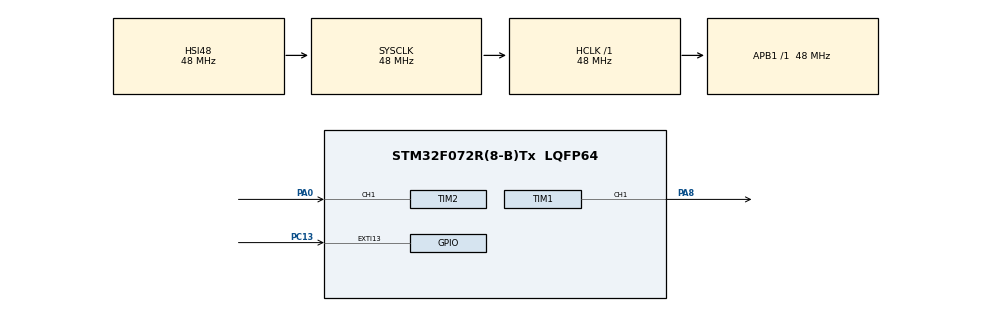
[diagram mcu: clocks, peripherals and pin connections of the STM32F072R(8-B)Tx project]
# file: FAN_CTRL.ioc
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Mcu.Family=STM32F0
Mcu.Name=STM32F072R(8-B)Tx
Mcu.Package=LQFP64
NVIC.EXTI4_15_IRQn=true\:0\:0\:false\:false\:true\:true\:true\:true
NVIC.TIM2_IRQn=true\:0\:0\:false\:false\:true\:true\:true\:true
PA0.GPIO_PuPd=GPIO_PULLUP
PA0.Signal=S_TIM2_CH1_ETR
PA13.Mode=Serial_Wire
PA13.Signal=SYS_SWDIO
PA14.Mode=Serial_Wire
PA14.Signal=SYS_SWCLK
PA8.Signal=S_TIM1_CH1
PC13.GPIO_ModeDefaultEXTI=GPIO_MODE_IT_FALLING
PC13.GPIO_PuPd=GPIO_PULLUP
PC13.Signal=GPXTI13
ProjectManager.HeapSize=0x200
ProjectManager.StackSize=0x400
ProjectManager.TargetToolchain=STM32CubeIDE
RCC.AHBFreq_Value=48000000
RCC.APB1Freq_Value=48000000
RCC.APB1TimFreq_Value=48000000
RCC.FLatency-AdvancedSettings=FLASH_LATENCY_1
RCC.HCLKFreq_Value=48000000
RCC.PLLDivider=RCC_PREDIV_DIV2
RCC.PLLMUL=RCC_PLL_MUL12
RCC.PREFETCH_ENABLE-AdvancedSettings=1
RCC.SYSCLKFreq_VALUE=48000000
RCC.SYSCLKSource=RCC_SYSCLKSOURCE_HSI48
SH.S_TIM1_CH1.0=TIM1_CH1,PWM Generation1 CH1
SH.S_TIM2_CH1_ETR.0=TIM2_CH1,Input_Capture1_from_TI1
TIM1.Channel-PWM\ Generation1\ CH1=TIM_CHANNEL_1
TIM1.Period=100-1
TIM1.Prescaler=48-1
TIM2.Channel-Input_Capture1_from_TI1=TIM_CHANNEL_1
TIM2.ICPolarity_CH1=TIM_INPUTCHANNELPOLARITY_RISING
TIM2.Period=0xffffffff-1
TIM2.Prescaler=48-1
VP_TIM1_VS_ClockSourceINT.Mode=Internal
VP_TIM2_VS_ClockSourceINT.Mode=Internal
board=NUCLEO-F072RB

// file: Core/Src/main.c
/* USER CODE BEGIN Header */
/**
  ******************************************************************************
  * @file           : main.c
  * @brief          : Main program body
  ******************************************************************************
  * @attention
  *
  * Copyright (c) 2024 STMicroelectronics.
  * All rights reserved.
  *
  * This software is licensed under terms that can be found in the LICENSE file
  * in the root directory of this software component.
  * If no LICENSE file comes with this software, it is provided AS-IS.
  *
  ******************************************************************************
  */
/* USER CODE END Header */
#include "main.h"

/* USER CODE BEGIN Includes */
#include "stdbool.h"
/* USER CODE END Includes */

TIM_HandleTypeDef htim1;
TIM_HandleTypeDef htim2;

void SystemClock_Config(void);
static void MX_GPIO_Init(void);
static void MX_TIM1_Init(void);
static void MX_TIM2_Init(void);

/* USER CODE BEGIN 0 */
static uint8_t duty = 0;
void HAL_GPIO_EXTI_Callback(uint16_t GPIO_Pin)
{
    if(GPIO_PIN_13 == GPIO_Pin) {
        if (GPIO_PIN_RESET == HAL_GPIO_ReadPin(GPIOC, GPIO_Pin))
        {
        	if (100 < (duty += 10)) {
        		duty = 0;
        	}
        	TIM1->CCR1 = duty;
        }
    }
}

static bool isFirstCap = true;
static uint32_t ic1 = 0;
static uint32_t ic2 = 0;
static float icFreq = 0;
#define REF_FREQ (48000000 / 48)

void HAL_TIM_IC_CaptureCallback(TIM_HandleTypeDef *htim)
{
	if (HAL_TIM_ACTIVE_CHANNEL_1 == htim->Channel)
	{
		if (true == isFirstCap)
		{
			ic1 = HAL_TIM_ReadCapturedValue(htim, TIM_CHANNEL_1);
			isFirstCap = false;
		}
		else
		{
			ic2 = HAL_TIM_ReadCapturedValue(htim, TIM_CHANNEL_1);  // read second value

			uint32_t diff;
			if (ic2 >= ic1)
			{
				diff = ic2 - ic1;
			}
			else
			{
				diff = (0xffffffff - ic1) + ic2;
			}

			ic1 = ic2;
			icFreq = REF_FREQ / diff;
		}
	}
}

/* USER CODE END 0 */

int main(void)
{

  /* MCU Configuration--------------------------------------------------------*/

  /* Reset of all peripherals, Initializes the Flash interface and the Systick. */
  HAL_Init();

  /* Configure the system clock */
  SystemClock_Config();

  /* Initialize all configured peripherals */
  MX_GPIO_Init();
  MX_TIM1_Init();
  MX_TIM2_Init();
  /* USER CODE BEGIN 2 */
  TIM1->CCR1 = 100;
  HAL_TIM_PWM_Start(&htim1, TIM_CHANNEL_1);
  HAL_TIM_IC_Start_IT(&htim2, TIM_CHANNEL_1);

  /* USER CODE END 2 */

  /* Infinite loop */
  while (1)
  {

  }
}

void SystemClock_Config(void)
{
  RCC_OscInitTypeDef RCC_OscInitStruct = {0};
  RCC_ClkInitTypeDef RCC_ClkInitStruct = {0};

  /** Initializes the RCC Oscillators according to the specified parameters
  * in the RCC_OscInitTypeDef structure.
  */
  RCC_OscInitStruct.OscillatorType = RCC_OSCILLATORTYPE_HSI48;
  RCC_OscInitStruct.HSI48State = RCC_HSI48_ON;
  RCC_OscInitStruct.PLL.PLLState = RCC_PLL_NONE;
  if (HAL_RCC_OscConfig(&RCC_OscInitStruct) != HAL_OK)
  {
    Error_Handler();
  }

  /** Initializes the CPU, AHB and APB buses clocks
  */
  RCC_ClkInitStruct.ClockType = RCC_CLOCKTYPE_HCLK|RCC_CLOCKTYPE_SYSCLK
                              |RCC_CLOCKTYPE_PCLK1;
  RCC_ClkInitStruct.SYSCLKSource = RCC_SYSCLKSOURCE_HSI48;
  RCC_ClkInitStruct.AHBCLKDivider = RCC_SYSCLK_DIV1;
  RCC_ClkInitStruct.APB1CLKDivider = RCC_HCLK_DIV1;

  if (HAL_RCC_ClockConfig(&RCC_ClkInitStruct, FLASH_LATENCY_1) != HAL_OK)
  {
    Error_Handler();
  }
}

static void MX_TIM1_Init(void)
{

  TIM_ClockConfigTypeDef sClockSourceConfig = {0};
  TIM_MasterConfigTypeDef sMasterConfig = {0};
  TIM_OC_InitTypeDef sConfigOC = {0};
  TIM_BreakDeadTimeConfigTypeDef sBreakDeadTimeConfig = {0};

  htim1.Instance = TIM1;
  htim1.Init.Prescaler = 48-1;
  htim1.Init.CounterMode = TIM_COUNTERMODE_UP;
  htim1.Init.Period = 100-1;
  htim1.Init.ClockDivision = TIM_CLOCKDIVISION_DIV1;
  htim1.Init.RepetitionCounter = 0;
  htim1.Init.AutoReloadPreload = TIM_AUTORELOAD_PRELOAD_DISABLE;
  if (HAL_TIM_Base_Init(&htim1) != HAL_OK)
  {
    Error_Handler();
  }
  sClockSourceConfig.ClockSource = TIM_CLOCKSOURCE_INTERNAL;
  if (HAL_TIM_ConfigClockSource(&htim1, &sClockSourceConfig) != HAL_OK)
  {
    Error_Handler();
  }
  if (HAL_TIM_PWM_Init(&htim1) != HAL_OK)
  {
    Error_Handler();
  }
  sMasterConfig.MasterOutputTrigger = TIM_TRGO_RESET;
  sMasterConfig.MasterSlaveMode = TIM_MASTERSLAVEMODE_DISABLE;
  if (HAL_TIMEx_MasterConfigSynchronization(&htim1, &sMasterConfig) != HAL_OK)
  {
    Error_Handler();
  }
  sConfigOC.OCMode = TIM_OCMODE_PWM1;
  sConfigOC.Pulse = 0;
  sConfigOC.OCPolarity = TIM_OCPOLARITY_HIGH;
  sConfigOC.OCNPolarity = TIM_OCNPOLARITY_HIGH;
  sConfigOC.OCFastMode = TIM_OCFAST_DISABLE;
  sConfigOC.OCIdleState = TIM_OCIDLESTATE_RESET;
  sConfigOC.OCNIdleState = TIM_OCNIDLESTATE_RESET;
  if (HAL_TIM_PWM_ConfigChannel(&htim1, &sConfigOC, TIM_CHANNEL_1) != HAL_OK)
  {
    Error_Handler();
  }
  sBreakDeadTimeConfig.OffStateRunMode = TIM_OSSR_DISABLE;
  sBreakDeadTimeConfig.OffStateIDLEMode = TIM_OSSI_DISABLE;
  sBreakDeadTimeConfig.LockLevel = TIM_LOCKLEVEL_OFF;
  sBreakDeadTimeConfig.DeadTime = 0;
  sBreakDeadTimeConfig.BreakState = TIM_BREAK_DISABLE;
  sBreakDeadTimeConfig.BreakPolarity = TIM_BREAKPOLARITY_HIGH;
  sBreakDeadTimeConfig.AutomaticOutput = TIM_AUTOMATICOUTPUT_DISABLE;
  if (HAL_TIMEx_ConfigBreakDeadTime(&htim1, &sBreakDeadTimeConfig) != HAL_OK)
  {
    Error_Handler();
  }
  HAL_TIM_MspPostInit(&htim1);

}

static void MX_TIM2_Init(void)
{

  TIM_ClockConfigTypeDef sClockSourceConfig = {0};
  TIM_MasterConfigTypeDef sMasterConfig = {0};
  TIM_IC_InitTypeDef sConfigIC = {0};

  htim2.Instance = TIM2;
  htim2.Init.Prescaler = 48-1;
  htim2.Init.CounterMode = TIM_COUNTERMODE_UP;
  htim2.Init.Period = 0xffffffff-1;
  htim2.Init.ClockDivision = TIM_CLOCKDIVISION_DIV1;
  htim2.Init.AutoReloadPreload = TIM_AUTORELOAD_PRELOAD_DISABLE;
  if (HAL_TIM_Base_Init(&htim2) != HAL_OK)
  {
    Error_Handler();
  }
  sClockSourceConfig.ClockSource = TIM_CLOCKSOURCE_INTERNAL;
  if (HAL_TIM_ConfigClockSource(&htim2, &sClockSourceConfig) != HAL_OK)
  {
    Error_Handler();
  }
  if (HAL_TIM_IC_Init(&htim2) != HAL_OK)
  {
    Error_Handler();
  }
  sMasterConfig.MasterOutputTrigger = TIM_TRGO_RESET;
  sMasterConfig.MasterSlaveMode = TIM_MASTERSLAVEMODE_DISABLE;
  if (HAL_TIMEx_MasterConfigSynchronization(&htim2, &sMasterConfig) != HAL_OK)
  {
    Error_Handler();
  }
  sConfigIC.ICPolarity = TIM_INPUTCHANNELPOLARITY_RISING;
  sConfigIC.ICSelection = TIM_ICSELECTION_DIRECTTI;
  sConfigIC.ICPrescaler = TIM_ICPSC_DIV1;
  sConfigIC.ICFilter = 0;
  if (HAL_TIM_IC_ConfigChannel(&htim2, &sConfigIC, TIM_CHANNEL_1) != HAL_OK)
  {
    Error_Handler();
  }

}

static void MX_GPIO_Init(void)
{
  GPIO_InitTypeDef GPIO_InitStruct = {0};

  /* GPIO Ports Clock Enable */
  __HAL_RCC_GPIOC_CLK_ENABLE();
  __HAL_RCC_GPIOA_CLK_ENABLE();

  /*Configure GPIO pin : PC13 */
  GPIO_InitStruct.Pin = GPIO_PIN_13;
  GPIO_InitStruct.Mode = GPIO_MODE_IT_FALLING;
  GPIO_InitStruct.Pull = GPIO_PULLUP;
  HAL_GPIO_Init(GPIOC, &GPIO_InitStruct);

  /* EXTI interrupt init*/
  HAL_NVIC_SetPriority(EXTI4_15_IRQn, 0, 0);
  HAL_NVIC_EnableIRQ(EXTI4_15_IRQn);

}

void Error_Handler(void)
{
  __disable_irq();
  while (1)
  {
  }
}
